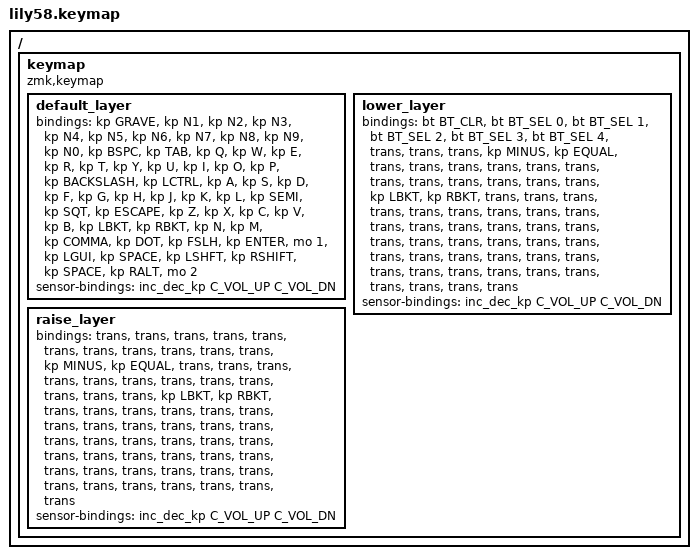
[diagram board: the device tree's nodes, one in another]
/*
 * Copyright (c) 2020 The ZMK Contributors
 *
 * SPDX-License-Identifier: MIT
 */

#include <behaviors.dtsi>
#include <dt-bindings/zmk/keys.h>
#include <dt-bindings/zmk/bt.h>
#include <dt-bindings/zmk/ext_power.h>

/ {
    keymap {
        compatible = "zmk,keymap";

        default_layer {
// ------------------------------------------------------------------------------------------------------------
// |  ESC  |  1  |  2  |  3   |  4   |  5   |                   |  6   |  7    |  8    |  9   |   0   |   `   |
// |  TAB  |  Q  |  W  |  E   |  R   |  T   |                   |  Y   |  U    |  I    |  O   |   P   |   -   |
// |  CTRL |  A  |  S  |  D   |  F   |  G   |                   |  H   |  J    |  K    |  L   |   ;   |   '   |
// | SHIFT |  Z  |  X  |  C   |  V   |  B   |   "["  |  |  "]"  |  N   |  M    |  ,    |  .   |   /   | SHIFT |
//                     | ALT  | GUI  | LOWER|  SPACE |  | ENTER | RAISE| BSPC  | GUI   |
            bindings = <
&kp GRAVE    &kp N1 &kp N2 &kp N3   &kp N4      &kp N5                           &kp N6 &kp N7      &kp N8    &kp N9  &kp N0   &kp BSPC
&kp TAB   &kp Q  &kp W  &kp E    &kp R       &kp T                            &kp Y  &kp U       &kp I     &kp O   &kp P    &kp BACKSLASH
&kp LCTRL &kp A  &kp S  &kp D    &kp F       &kp G                            &kp H  &kp J       &kp K     &kp L   &kp SEMI &kp SQT
&kp ESCAPE &kp Z  &kp X  &kp C    &kp V       &kp B        &kp LBKT     &kp RBKT   &kp N  &kp M       &kp COMMA &kp DOT &kp FSLH &kp ENTER
                        &mo 1    &kp LGUI    &kp SPACE &kp LSHFT    &kp RSHIFT  &kp SPACE &kp RALT &mo 2
            >;
            sensor-bindings = <&inc_dec_kp C_VOL_UP C_VOL_DN>;
        };

        lower_layer {
// ------------------------------------------------------------------------------------------------------------
// | BTCLR | BT1 | BT2 |  BT3 |  BT4 |  BT5 |                   |      |       |       |      |       |       |
// |  F1   |  F2 |  F3 |  F4  |  F5  |  F6  |                   |  F7  |  F8   |  F9   |  F10 |  F11  |  F12  |
// |   `   |  !  |  @  |  #   |  $   |  %   |                   |  ^   |  &    |  *    |  (   |   )   |   ~   |
// |       |     |     |      |      |      |        |  |       |      |  _    |  +    |  {   |   }   |  "|"  |
//                     |      |      |      |        |  |       |      |       |       |
// &bt BT_CLR &bt BT_SEL 0     &bt BT_SEL 1      &bt BT_SEL 2      &bt BT_SEL 3 &bt BT_SEL 4                 &trans    &trans    &trans    &trans    &trans    &trans
            bindings = <
&bt BT_CLR  &bt BT_SEL 0      &bt BT_SEL 1      &bt BT_SEL 2     &bt BT_SEL 3  &bt BT_SEL 4                       &trans    &trans    &trans  &kp MINUS      &kp EQUAL  &trans
&trans      &trans           &trans            &trans            &trans       &trans          &trans    &trans    &trans    &trans    &trans  &kp LBKT       &kp RBKT   &trans
&trans      &trans           &trans            &trans            &trans       &trans          &trans    &trans    &trans    &trans    &trans  &trans      &trans  &trans
&trans      &trans           &trans            &trans            &trans       &trans          &trans    &trans    &trans    &trans    &trans  &trans      &trans  &trans
                                               &trans            &trans       &trans          &trans    &trans    &trans    &trans    &trans
            >;

            sensor-bindings = <&inc_dec_kp C_VOL_UP C_VOL_DN>;
        };

        raise_layer {
// ------------------------------------------------------------------------------------------------------------
// |       |     |     |      |      |      |                   |      |       |       |      |       |       |
// |   `   |  1  |  2  |  3   |  4   |  5   |                   |  6   |   7   |   8   |  9   |   0   |       |
// |   F1  |  F2 |  F3 |  F4  |  F5  |  F6  |                   |      |   <-  |   v   |  ^   |  ->   |       |
// |   F7  |  F8 |  F9 |  F10 |  F11 |  F12 |        |  |       |  +   |   -   |   =   |  [   |   ]   |   \   |
//                     |      |      |      |        |  |       |      |       |       |
            bindings = <
&trans      &trans           &trans            &trans            &trans       &trans          &trans    &trans    &trans    &trans    &trans  &kp MINUS      &kp EQUAL  &trans
&trans      &trans           &trans            &trans            &trans       &trans          &trans    &trans    &trans    &trans    &trans  &kp LBKT       &kp RBKT   &trans
&trans      &trans           &trans            &trans            &trans       &trans          &trans    &trans    &trans    &trans    &trans  &trans      &trans  &trans
&trans      &trans           &trans            &trans            &trans       &trans          &trans    &trans    &trans    &trans    &trans  &trans      &trans  &trans
                                              &trans            &trans      &trans    &trans   &trans    &trans      &trans    &trans
            >;

            sensor-bindings = <&inc_dec_kp C_VOL_UP C_VOL_DN>;
        };
    };
};
